# STM32F100xx register map
File version: 1.1
Registers are 32-bit, read-write, reset 0x0 unless marked. A register's access mark holds for its fields unless they carry their own. Offsets are from the block's base; [hi:lo] are bit positions; {n}, {i} and the like mark numbered series; 'fields as' and 'values as' point back to an identical list.

## FSMC — Flexible static memory controller
Base 0xA0000000
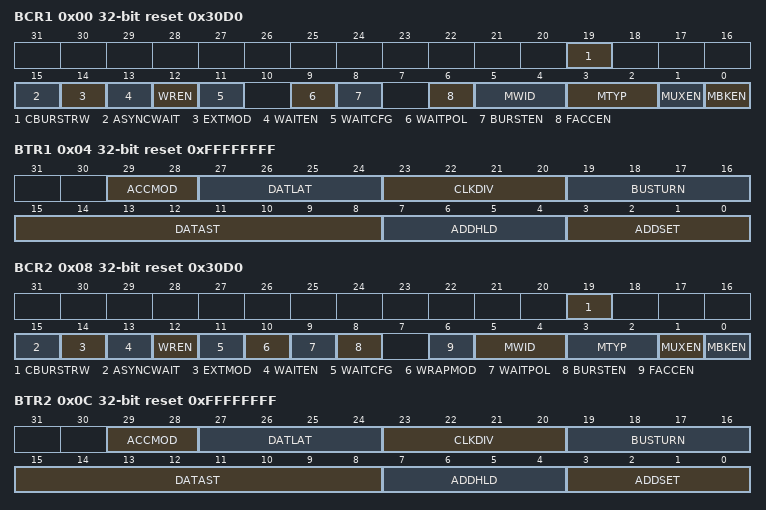
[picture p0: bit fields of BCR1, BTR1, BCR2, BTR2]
0x00 BCR1 reset 0x30D0 — SRAM/NOR-Flash chip-select control register 1
  [19] CBURSTRW, [15] ASYNCWAIT, [14] EXTMOD, [13] WAITEN, [12] WREN, [11] WAITCFG, [9] WAITPOL, [8] BURSTEN, [6] FACCEN, [5:4] MWID, [3:2] MTYP, [1] MUXEN, [0] MBKEN
0x04 BTR1 reset 0xFFFFFFFF — SRAM/NOR-Flash chip-select timing register 1
  [29:28] ACCMOD, [27:24] DATLAT, [23:20] CLKDIV, [19:16] BUSTURN, [15:8] DATAST, [7:4] ADDHLD, [3:0] ADDSET
0x08 BCR2 reset 0x30D0 — SRAM/NOR-Flash chip-select control register 2
  [19] CBURSTRW, [15] ASYNCWAIT, [14] EXTMOD, [13] WAITEN, [12] WREN, [11] WAITCFG, [10] WRAPMOD, [9] WAITPOL, [8] BURSTEN, [6] FACCEN, [5:4] MWID, [3:2] MTYP, [1] MUXEN, [0] MBKEN
0x0C BTR2 reset 0xFFFFFFFF — SRAM/NOR-Flash chip-select timing register 2
  fields as BTR1
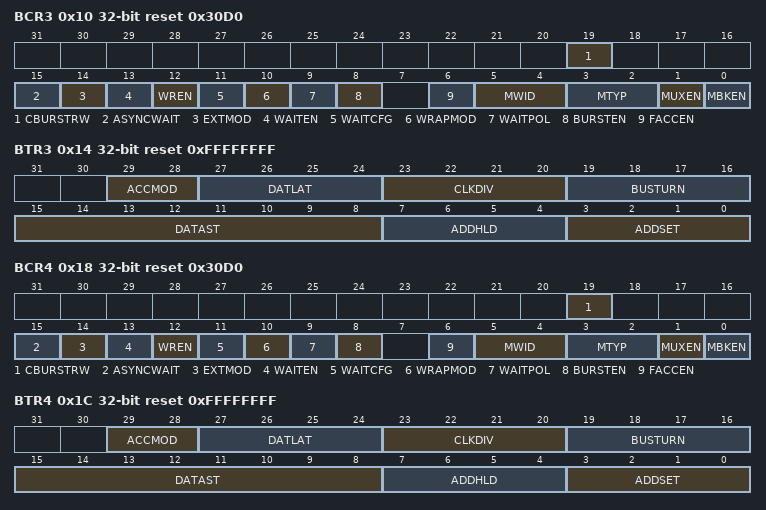
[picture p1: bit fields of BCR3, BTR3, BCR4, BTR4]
0x10 BCR3 reset 0x30D0 — SRAM/NOR-Flash chip-select control register 3
  fields as BCR2
0x14 BTR3 reset 0xFFFFFFFF — SRAM/NOR-Flash chip-select timing register 3
  fields as BTR1
0x18 BCR4 reset 0x30D0 — SRAM/NOR-Flash chip-select control register 4
  fields as BCR2
0x1C BTR4 reset 0xFFFFFFFF — SRAM/NOR-Flash chip-select timing register 4
  fields as BTR1
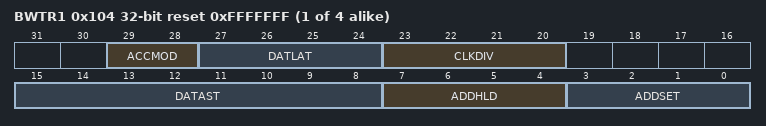
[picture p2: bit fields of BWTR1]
{0xFC+8i} BWTR{i} reset 0xFFFFFFF (i=1..4) — SRAM/NOR-Flash write timing registers {i}
  [29:28] ACCMOD, [27:24] DATLAT, [23:20] CLKDIV, [15:8] DATAST, [7:4] ADDHLD, [3:0] ADDSET

## PWR — Power control
Base 0x40007000
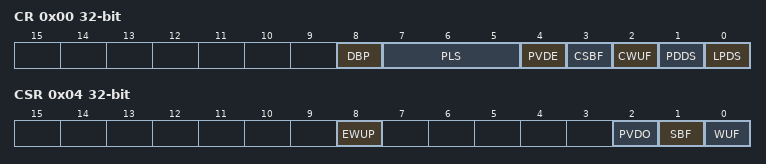
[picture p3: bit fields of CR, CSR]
0x00 CR — Power control register (PWR_CR)
  [8] DBP — Disable Backup Domain write protection
  [7:5] PLS — PVD Level Selection
  [4] PVDE — Power Voltage Detector Enable
  [3] CSBF — Clear STANDBY Flag
  [2] CWUF — Clear Wake-up Flag
  [1] PDDS — Power Down Deep Sleep
  [0] LPDS — Low Power Deep Sleep
0x04 CSR access per field — Power control register (PWR_CR)
  [8] EWUP rw — Enable WKUP pin
  [2] PVDO ro — PVD Output
  [1] SBF ro — STANDBY Flag
  [0] WUF ro — Wake-Up Flag

## GPIOA — General purpose I/O
Base 0x40010800
Same registers: GPIOB 0x40010C00, GPIOC 0x40011000, GPIOD 0x40011400, GPIOE 0x40011800, GPIOF 0x40011C00, GPIOG 0x40012000
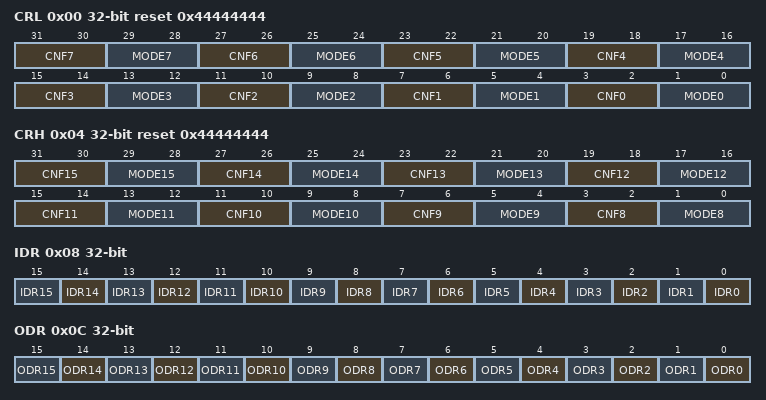
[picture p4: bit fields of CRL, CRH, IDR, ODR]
0x00 CRL reset 0x44444444 — Port configuration register low (GPIOn_CRL)
  [31:30] CNF7 — Port n.7 configuration bits
    0=Push_Pull; 1=Open-Drain (reset state); 2=Alt_Push_Pull (Alternate Function Push-Pull); 3=Alt_Open_Drain (Alternate Function Open-Drain); 0=Analog_Input; 1=Digital_Input (Digital Floating Input (reset state)); 2=Digital_Input_Pull (Digital Input with a weak pull resistor)
  [29:28] MODE7 — Port n.7 mode bits
    0=Input mode (reset state); 1=Output_10MHz (Output mode, max speed 10MHz); 2=Output_2MHz (Output mode, max speed 2MHz); 3=Output_50MHz (Output mode, max speed 50MHz)
  [27:26] CNF6 — Port n.6 configuration bits
    values as CNF7
  [25:24] MODE6 — Port n.6 mode bits
    values as MODE7
  [23:22] CNF5 — Port n.5 configuration bits
    values as CNF7
  [21:20] MODE5 — Port n.5 mode bits
    values as MODE7
  [19:18] CNF4 — Port n.4 configuration bits
    values as CNF7
  [17:16] MODE4 — Port n.4 mode bits
    values as MODE7
  [15:14] CNF3 — Port n.3 configuration bits
    values as CNF7
  [13:12] MODE3 — Port n.3 mode bits
    values as MODE7
  [11:10] CNF2 — Port n.2 configuration bits
    values as CNF7
  [9:8] MODE2 — Port n.2 mode bits
    values as MODE7
  [7:6] CNF1 — Port n.1 configuration bits
    values as CNF7
  [5:4] MODE1 — Port n.1 mode bits
    values as MODE7
  [3:2] CNF0 — Port n.0 configuration bits
    values as CNF7
  [1:0] MODE0 — Port n.0 mode bits
    values as MODE7
0x04 CRH reset 0x44444444 — Port configuration register high (GPIOn_CRL)
  [31:30] CNF15 — Port n.15 configuration bits
    0=Push_Pull; 1=Open-Drain (reset state); 2=Alt_Push_Pull (Alternate Function Push-Pull); 3=Alt_Open_Drain (Alternate Function Open-Drain)
  [29:28] MODE15 — Port n.15 mode bits
    values as CRL.MODE7
  [27:26] CNF14 — Port n.14 configuration bits
    values as CNF15
  [25:24] MODE14 — Port n.14 mode bits
    values as CRL.MODE7
  [23:22] CNF13 — Port n.13 configuration bits
    values as CNF15
  [21:20] MODE13 — Port n.13 mode bits
    values as CRL.MODE7
  [19:18] CNF12 — Port n.12 configuration bits
    values as CNF15
  [17:16] MODE12 — Port n.12 mode bits
    values as CRL.MODE7
  [15:14] CNF11 — Port n.11 configuration bits
    values as CNF15
  [13:12] MODE11 — Port n.11 mode bits
    values as CRL.MODE7
  [11:10] CNF10 — Port n.10 configuration bits
    values as CNF15
  [9:8] MODE10 — Port n.10 mode bits
    values as CRL.MODE7
  [7:6] CNF9 — Port n.9 configuration bits
    values as CNF15
  [5:4] MODE9 — Port n.9 mode bits
    values as CRL.MODE7
  [3:2] CNF8 — Port n.8 configuration bits
    values as CNF15
  [1:0] MODE8 — Port n.8 mode bits
    values as CRL.MODE7
0x08 IDR ro — Port input data register (GPIOn_IDR)
  [n] IDR{n} (n=0..15) — Port input data
0x0C ODR — Port output data register (GPIOn_ODR)
  [n] ODR{n} (n=0..15) — Port output data
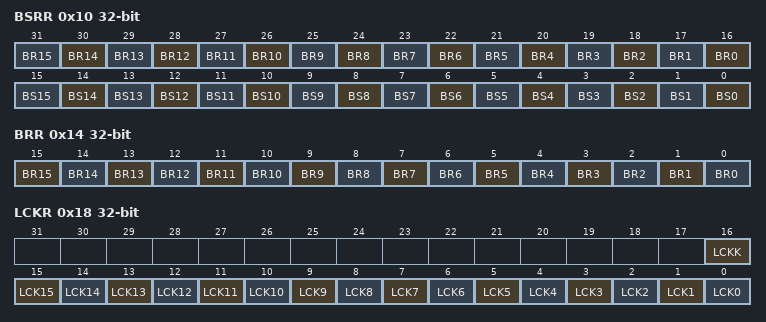
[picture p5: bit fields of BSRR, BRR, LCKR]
0x10 BSRR wo — Port bit set/reset register (GPIOn_BSRR)
  [n+16] BR{n} (n=0..15) — Reset bit {n}
    on write: 1=Resets the corresponding ODRx bit
  [n] BS{n} (n=0..15) — Set bit {n}
    on write: 1=Set (Sets the corresponding ODRx bit)
0x14 BRR wo — Port bit reset register (GPIOn_BRR)
  [n] BR{n} (n=3..15) — Reset bit {n}
  [2] BR2 — Reset bit 1
  [1] BR1 — Reset bit 1
  [0] BR0 — Reset bit 0
0x18 LCKR — Port configuration lock register
  [16] LCKK — Lock key
  [n] LCK{n} (n=0..15) — Port A Lock bit {n}
